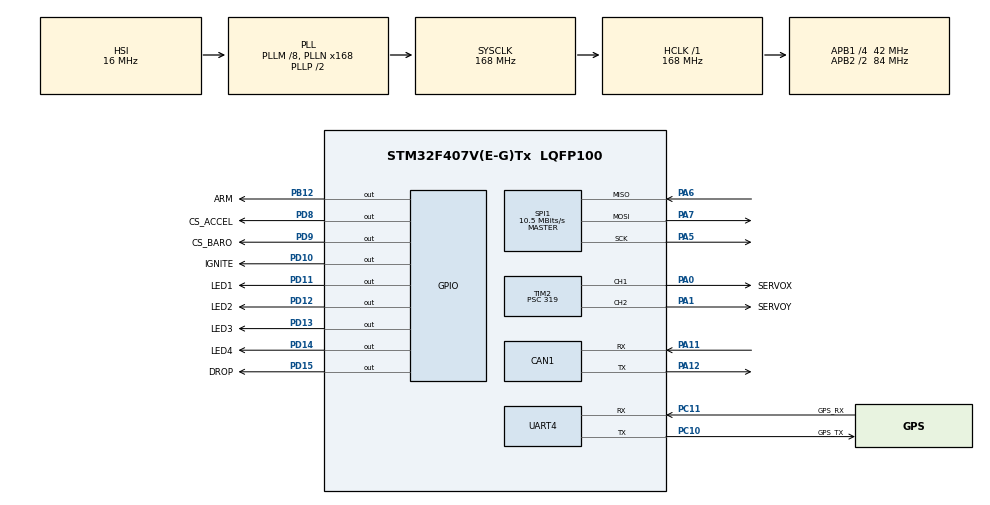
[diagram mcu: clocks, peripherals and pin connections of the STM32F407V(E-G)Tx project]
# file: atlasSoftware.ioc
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CAN1.BS1=CAN_BS1_1TQ
CAN1.BS2=CAN_BS2_1TQ
CAN1.CalculateTimeQuantum=380.95238095238096
FREERTOS.Tasks01=defaultTask,0,128,StartDefaultTask,Default,NULL
Mcu.Family=STM32F4
Mcu.Name=STM32F407V(E-G)Tx
Mcu.Package=LQFP100
NVIC.CAN1_RX0_IRQn=true\:5\:0\:false\:false\:true\:true\:true
NVIC.CAN1_TX_IRQn=true\:5\:0\:false\:false\:true\:true\:true
NVIC.PriorityGroup=NVIC_PRIORITYGROUP_4
NVIC.TIM1_UP_TIM10_IRQn=true\:0\:0\:false\:false\:true\:false\:false
NVIC.TimeBase=TIM1_UP_TIM10_IRQn
NVIC.TimeBaseIP=TIM1
PA0-WKUP.GPIO_Label=SERVOX
PA0-WKUP.Signal=S_TIM2_CH1_ETR
PA1.GPIO_Label=SERVOY
PA1.Signal=S_TIM2_CH2
PA11.Mode=Master
PA11.Signal=CAN1_RX
PA12.Mode=Master
PA12.Signal=CAN1_TX
PA13.Mode=JTAG_5_pins
PA13.Signal=SYS_JTMS-SWDIO
PA14.Mode=JTAG_5_pins
PA14.Signal=SYS_JTCK-SWCLK
PA15.Mode=JTAG_5_pins
PA15.Signal=SYS_JTDI
PA5.Mode=Full_Duplex_Master
PA5.Signal=SPI1_SCK
PA6.Mode=Full_Duplex_Master
PA6.Signal=SPI1_MISO
PA7.Mode=Full_Duplex_Master
PA7.Signal=SPI1_MOSI
PB12.GPIO_Label=ARM
PB12.Signal=GPIO_Output
PB3.Mode=JTAG_5_pins
PB3.Signal=SYS_JTDO-SWO
PB4.Mode=JTAG_5_pins
PB4.Signal=SYS_JTRST
PC10.GPIO_Label=GPS_TX
PC10.Mode=Asynchronous
PC10.Signal=UART4_TX
PC11.GPIO_Label=GPS_RX
PC11.Mode=Asynchronous
PC11.Signal=UART4_RX
PD10.GPIO_Label=IGNITE
PD10.Signal=GPIO_Output
PD11.GPIO_Label=LED1
PD11.Signal=GPIO_Output
PD12.GPIO_Label=LED2
PD12.Signal=GPIO_Output
PD13.GPIO_Label=LED3
PD13.Signal=GPIO_Output
PD14.GPIO_Label=LED4
PD14.Signal=GPIO_Output
PD15.GPIO_Label=DROP
PD15.Signal=GPIO_Output
PD8.GPIO_Label=CS_ACCEL
PD8.Signal=GPIO_Output
PD9.GPIO_Label=CS_BARO
PD9.Signal=GPIO_Output
ProjectManager.HeapSize=0x200
ProjectManager.StackSize=0x400
ProjectManager.TargetToolchain=TrueSTUDIO
RCC.48MHZClocksFreq_Value=84000000
RCC.AHBFreq_Value=168000000
RCC.APB1CLKDivider=RCC_HCLK_DIV4
RCC.APB1Freq_Value=42000000
RCC.APB1TimFreq_Value=84000000
RCC.APB2CLKDivider=RCC_HCLK_DIV2
RCC.APB2Freq_Value=84000000
RCC.APB2TimFreq_Value=168000000
RCC.CortexFreq_Value=168000000
RCC.HCLKFreq_Value=168000000
RCC.HSE_VALUE=25000000
RCC.HSI_VALUE=16000000
RCC.LSE_VALUE=32768
RCC.PLLM=8
RCC.PLLN=168
RCC.SYSCLKFreq_VALUE=168000000
RCC.SYSCLKSource=RCC_SYSCLKSOURCE_PLLCLK
RCC.VCOOutputFreq_Value=336000000
SH.S_TIM2_CH1_ETR.0=TIM2_CH1,PWM Generation1 CH1
SH.S_TIM2_CH2.0=TIM2_CH2,PWM Generation2 CH2
SPI1.BaudRatePrescaler=SPI_BAUDRATEPRESCALER_8
SPI1.CalculateBaudRate=10.5 MBits/s
SPI1.Direction=SPI_DIRECTION_2LINES
SPI1.Mode=SPI_MODE_MASTER
SPI1.VirtualType=VM_MASTER
TIM2.Channel-PWM\ Generation1\ CH1=TIM_CHANNEL_1
TIM2.Channel-PWM\ Generation2\ CH2=TIM_CHANNEL_2
TIM2.Period=10000
TIM2.Prescaler=319
UART4.VirtualMode=Asynchronous
VP_FREERTOS_VS_ENABLE.Mode=Enabled
VP_SYS_VS_tim1.Mode=TIM1
board=custom

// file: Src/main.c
/* USER CODE BEGIN Header */
/**
  ******************************************************************************
  * @file           : main.c
  * @brief          : Main program body
  ******************************************************************************
  * This notice applies to any and all portions of this file
  * that are not between comment pairs USER CODE BEGIN and
  * USER CODE END. Other portions of this file, whether
  * inserted by the user or by software development tools
  * are owned by their respective copyright owners.
  *
  * Copyright (c) 2020 STMicroelectronics International N.V.
  * All rights reserved.
  *
  * Redistribution and use in source and binary forms, with or without
  * modification, are permitted, provided that the following conditions are met:
  *
  * 1. Redistribution of source code must retain the above copyright notice,
  *    this list of conditions and the following disclaimer.
  * 2. Redistributions in binary form must reproduce the above copyright notice,
  *    this list of conditions and the following disclaimer in the documentation
  *    and/or other materials provided with the distribution.
  * 3. Neither the name of STMicroelectronics nor the names of other
  *    contributors to this software may be used to endorse or promote products
  *    derived from this software without specific written permission.
  * 4. This software, including modifications and/or derivative works of this
  *    software, must execute solely and exclusively on microcontroller or
  *    microprocessor devices manufactured by or for STMicroelectronics.
  * 5. Redistribution and use of this software other than as permitted under
  *    this license is void and will automatically terminate your rights under
  *    this license.
  *
  * THIS SOFTWARE IS PROVIDED BY STMICROELECTRONICS AND CONTRIBUTORS "AS IS"
  * AND ANY EXPRESS, IMPLIED OR STATUTORY WARRANTIES, INCLUDING, BUT NOT
  * LIMITED TO, THE IMPLIED WARRANTIES OF MERCHANTABILITY, FITNESS FOR A
  * PARTICULAR PURPOSE AND NON-INFRINGEMENT OF THIRD PARTY INTELLECTUAL PROPERTY
  * RIGHTS ARE DISCLAIMED TO THE FULLEST EXTENT PERMITTED BY LAW. IN NO EVENT
  * SHALL STMICROELECTRONICS OR CONTRIBUTORS BE LIABLE FOR ANY DIRECT, INDIRECT,
  * INCIDENTAL, SPECIAL, EXEMPLARY, OR CONSEQUENTIAL DAMAGES (INCLUDING, BUT NOT
  * LIMITED TO, PROCUREMENT OF SUBSTITUTE GOODS OR SERVICES; LOSS OF USE, DATA,
  * OR PROFITS; OR BUSINESS INTERRUPTION) HOWEVER CAUSED AND ON ANY THEORY OF
  * LIABILITY, WHETHER IN CONTRACT, STRICT LIABILITY, OR TORT (INCLUDING
  * NEGLIGENCE OR OTHERWISE) ARISING IN ANY WAY OUT OF THE USE OF THIS SOFTWARE,
  * EVEN IF ADVISED OF THE POSSIBILITY OF SUCH DAMAGE.
  *
  ******************************************************************************
  */
/* USER CODE END Header */

#include "main.h"
#include "cmsis_os.h"

CAN_HandleTypeDef hcan1;

SPI_HandleTypeDef hspi1;

TIM_HandleTypeDef htim2;

UART_HandleTypeDef huart4;

osThreadId defaultTaskHandle;

void SystemClock_Config(void);
static void MX_GPIO_Init(void);
static void MX_CAN1_Init(void);
static void MX_SPI1_Init(void);
static void MX_TIM2_Init(void);
static void MX_UART4_Init(void);
void StartDefaultTask(void const * argument);

int main(void)
{

  /* MCU Configuration--------------------------------------------------------*/

  /* Reset of all peripherals, Initializes the Flash interface and the Systick. */
  HAL_Init();

  /* Configure the system clock */
  SystemClock_Config();

  /* Initialize all configured peripherals */
  MX_GPIO_Init();
  MX_CAN1_Init();
  MX_SPI1_Init();
  MX_TIM2_Init();
  MX_UART4_Init();
  /* USER CODE BEGIN 2 */
  initRTOSObjects();
  /* USER CODE END 2 */

  /* Create the thread(s) */
  /* definition and creation of defaultTask */
  osThreadDef(defaultTask, StartDefaultTask, osPriorityNormal, 0, 128);
  defaultTaskHandle = osThreadCreate(osThread(defaultTask), NULL);

  /* Start scheduler */
  osKernelStart();

  /* We should never get here as control is now taken by the scheduler */

  /* Infinite loop */
  while (1)
  {

  }
}

void SystemClock_Config(void)
{
  RCC_OscInitTypeDef RCC_OscInitStruct = {0};
  RCC_ClkInitTypeDef RCC_ClkInitStruct = {0};

  /**Configure the main internal regulator output voltage
  */
  __HAL_RCC_PWR_CLK_ENABLE();
  __HAL_PWR_VOLTAGESCALING_CONFIG(PWR_REGULATOR_VOLTAGE_SCALE1);
  /**Initializes the CPU, AHB and APB busses clocks
  */
  RCC_OscInitStruct.OscillatorType = RCC_OSCILLATORTYPE_HSI;
  RCC_OscInitStruct.HSIState = RCC_HSI_ON;
  RCC_OscInitStruct.HSICalibrationValue = RCC_HSICALIBRATION_DEFAULT;
  RCC_OscInitStruct.PLL.PLLState = RCC_PLL_ON;
  RCC_OscInitStruct.PLL.PLLSource = RCC_PLLSOURCE_HSI;
  RCC_OscInitStruct.PLL.PLLM = 8;
  RCC_OscInitStruct.PLL.PLLN = 168;
  RCC_OscInitStruct.PLL.PLLP = RCC_PLLP_DIV2;
  RCC_OscInitStruct.PLL.PLLQ = 4;
  if (HAL_RCC_OscConfig(&RCC_OscInitStruct) != HAL_OK)
  {
    Error_Handler();
  }
  /**Initializes the CPU, AHB and APB busses clocks
  */
  RCC_ClkInitStruct.ClockType = RCC_CLOCKTYPE_HCLK|RCC_CLOCKTYPE_SYSCLK
                              |RCC_CLOCKTYPE_PCLK1|RCC_CLOCKTYPE_PCLK2;
  RCC_ClkInitStruct.SYSCLKSource = RCC_SYSCLKSOURCE_PLLCLK;
  RCC_ClkInitStruct.AHBCLKDivider = RCC_SYSCLK_DIV1;
  RCC_ClkInitStruct.APB1CLKDivider = RCC_HCLK_DIV4;
  RCC_ClkInitStruct.APB2CLKDivider = RCC_HCLK_DIV2;

  if (HAL_RCC_ClockConfig(&RCC_ClkInitStruct, FLASH_LATENCY_5) != HAL_OK)
  {
    Error_Handler();
  }
}

static void MX_CAN1_Init(void)
{

  hcan1.Instance = CAN1;
  hcan1.Init.Prescaler = 16;
  hcan1.Init.Mode = CAN_MODE_NORMAL;
  hcan1.Init.SyncJumpWidth = CAN_SJW_1TQ;
  hcan1.Init.TimeSeg1 = CAN_BS1_1TQ;
  hcan1.Init.TimeSeg2 = CAN_BS2_1TQ;
  hcan1.Init.TimeTriggeredMode = DISABLE;
  hcan1.Init.AutoBusOff = DISABLE;
  hcan1.Init.AutoWakeUp = DISABLE;
  hcan1.Init.AutoRetransmission = DISABLE;
  hcan1.Init.ReceiveFifoLocked = DISABLE;
  hcan1.Init.TransmitFifoPriority = DISABLE;
  if (HAL_CAN_Init(&hcan1) != HAL_OK)
  {
    Error_Handler();
  }

}

static void MX_SPI1_Init(void)
{

  /* SPI1 parameter configuration*/
  hspi1.Instance = SPI1;
  hspi1.Init.Mode = SPI_MODE_MASTER;
  hspi1.Init.Direction = SPI_DIRECTION_2LINES;
  hspi1.Init.DataSize = SPI_DATASIZE_8BIT;
  hspi1.Init.CLKPolarity = SPI_POLARITY_LOW;
  hspi1.Init.CLKPhase = SPI_PHASE_1EDGE;
  hspi1.Init.NSS = SPI_NSS_SOFT;
  hspi1.Init.BaudRatePrescaler = SPI_BAUDRATEPRESCALER_8;
  hspi1.Init.FirstBit = SPI_FIRSTBIT_MSB;
  hspi1.Init.TIMode = SPI_TIMODE_DISABLE;
  hspi1.Init.CRCCalculation = SPI_CRCCALCULATION_DISABLE;
  hspi1.Init.CRCPolynomial = 10;
  if (HAL_SPI_Init(&hspi1) != HAL_OK)
  {
    Error_Handler();
  }

}

static void MX_TIM2_Init(void)
{

  TIM_MasterConfigTypeDef sMasterConfig = {0};
  TIM_OC_InitTypeDef sConfigOC = {0};

  htim2.Instance = TIM2;
  htim2.Init.Prescaler = 319;
  htim2.Init.CounterMode = TIM_COUNTERMODE_UP;
  htim2.Init.Period = 10000;
  htim2.Init.ClockDivision = TIM_CLOCKDIVISION_DIV1;
  if (HAL_TIM_PWM_Init(&htim2) != HAL_OK)
  {
    Error_Handler();
  }
  sMasterConfig.MasterOutputTrigger = TIM_TRGO_RESET;
  sMasterConfig.MasterSlaveMode = TIM_MASTERSLAVEMODE_DISABLE;
  if (HAL_TIMEx_MasterConfigSynchronization(&htim2, &sMasterConfig) != HAL_OK)
  {
    Error_Handler();
  }
  sConfigOC.OCMode = TIM_OCMODE_PWM1;
  sConfigOC.Pulse = 0;
  sConfigOC.OCPolarity = TIM_OCPOLARITY_HIGH;
  sConfigOC.OCFastMode = TIM_OCFAST_DISABLE;
  if (HAL_TIM_PWM_ConfigChannel(&htim2, &sConfigOC, TIM_CHANNEL_1) != HAL_OK)
  {
    Error_Handler();
  }
  if (HAL_TIM_PWM_ConfigChannel(&htim2, &sConfigOC, TIM_CHANNEL_2) != HAL_OK)
  {
    Error_Handler();
  }
  HAL_TIM_MspPostInit(&htim2);

}

static void MX_UART4_Init(void)
{

  huart4.Instance = UART4;
  huart4.Init.BaudRate = 115200;
  huart4.Init.WordLength = UART_WORDLENGTH_8B;
  huart4.Init.StopBits = UART_STOPBITS_1;
  huart4.Init.Parity = UART_PARITY_NONE;
  huart4.Init.Mode = UART_MODE_TX_RX;
  huart4.Init.HwFlowCtl = UART_HWCONTROL_NONE;
  huart4.Init.OverSampling = UART_OVERSAMPLING_16;
  if (HAL_UART_Init(&huart4) != HAL_OK)
  {
    Error_Handler();
  }

}

static void MX_GPIO_Init(void)
{
  GPIO_InitTypeDef GPIO_InitStruct = {0};

  /* GPIO Ports Clock Enable */
  __HAL_RCC_GPIOA_CLK_ENABLE();
  __HAL_RCC_GPIOB_CLK_ENABLE();
  __HAL_RCC_GPIOD_CLK_ENABLE();
  __HAL_RCC_GPIOC_CLK_ENABLE();

  /*Configure GPIO pin Output Level */
  HAL_GPIO_WritePin(ARM_GPIO_Port, ARM_Pin, GPIO_PIN_RESET);

  /*Configure GPIO pin Output Level */
  HAL_GPIO_WritePin(GPIOD, CS_ACCEL_Pin|CS_BARO_Pin|IGNITE_Pin|LED1_Pin
                          |LED2_Pin|LED3_Pin|LED4_Pin|DROP_Pin, GPIO_PIN_RESET);

  /*Configure GPIO pin : ARM_Pin */
  GPIO_InitStruct.Pin = ARM_Pin;
  GPIO_InitStruct.Mode = GPIO_MODE_OUTPUT_PP;
  GPIO_InitStruct.Pull = GPIO_NOPULL;
  GPIO_InitStruct.Speed = GPIO_SPEED_FREQ_LOW;
  HAL_GPIO_Init(ARM_GPIO_Port, &GPIO_InitStruct);

  /*Configure GPIO pins : CS_ACCEL_Pin CS_BARO_Pin IGNITE_Pin LED1_Pin
                           LED2_Pin LED3_Pin LED4_Pin DROP_Pin */
  GPIO_InitStruct.Pin = CS_ACCEL_Pin|CS_BARO_Pin|IGNITE_Pin|LED1_Pin
                          |LED2_Pin|LED3_Pin|LED4_Pin|DROP_Pin;
  GPIO_InitStruct.Mode = GPIO_MODE_OUTPUT_PP;
  GPIO_InitStruct.Pull = GPIO_NOPULL;
  GPIO_InitStruct.Speed = GPIO_SPEED_FREQ_LOW;
  HAL_GPIO_Init(GPIOD, &GPIO_InitStruct);

}

void StartDefaultTask(void const * argument)
{

  for(;;)
  {
    osDelay(1);
  }
}

void HAL_TIM_PeriodElapsedCallback(TIM_HandleTypeDef *htim)
{
  if (htim->Instance == TIM1) {
    HAL_IncTick();
  }
}

void Error_Handler(void)
{
}

/************************ (C) COPYRIGHT STMicroelectronics *****END OF FILE****/
